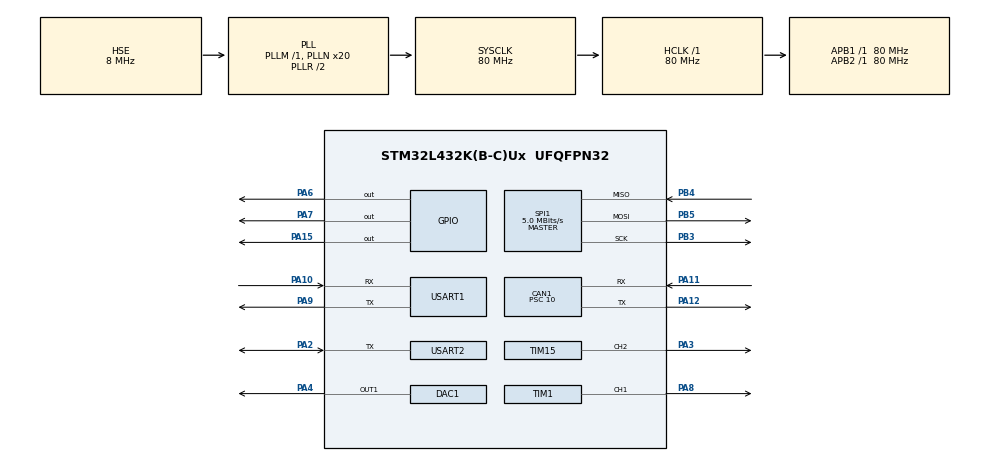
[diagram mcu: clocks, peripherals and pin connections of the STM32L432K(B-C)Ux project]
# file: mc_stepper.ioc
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ADC1.Channel-0\#ChannelRegularConversion=ADC_CHANNEL_VREFINT
ADC1.Channel-1\#ChannelRegularConversion=ADC_CHANNEL_TEMPSENSOR
ADC1.NbrOfConversion=2
ADC1.NbrOfConversionFlag=1
ADC1.OffsetNumber-0\#ChannelRegularConversion=ADC_OFFSET_NONE
ADC1.OffsetNumber-1\#ChannelRegularConversion=ADC_OFFSET_NONE
ADC1.Overrun=ADC_OVR_DATA_OVERWRITTEN
ADC1.OversamplingMode=DISABLE
ADC1.Rank-0\#ChannelRegularConversion=1
ADC1.Rank-1\#ChannelRegularConversion=2
ADC1.SamplingTime-0\#ChannelRegularConversion=ADC_SAMPLETIME_640CYCLES_5
ADC1.SamplingTime-1\#ChannelRegularConversion=ADC_SAMPLETIME_640CYCLES_5
ADC1.master=1
CAN1.ABOM=ENABLE
CAN1.BS1=CAN_BS1_13TQ
CAN1.BS2=CAN_BS2_2TQ
CAN1.CalculateBaudRate=500000
CAN1.CalculateTimeBit=2000
CAN1.CalculateTimeQuantum=125.0
CAN1.NART=ENABLE
CAN1.Prescaler=10
Dma.ADC1.3.Direction=DMA_PERIPH_TO_MEMORY
Dma.ADC1.3.Instance=DMA1_Channel1
Dma.ADC1.3.MemDataAlignment=DMA_MDATAALIGN_WORD
Dma.ADC1.3.MemInc=DMA_MINC_ENABLE
Dma.ADC1.3.Mode=DMA_NORMAL
Dma.ADC1.3.PeriphDataAlignment=DMA_PDATAALIGN_WORD
Dma.ADC1.3.PeriphInc=DMA_PINC_DISABLE
Dma.ADC1.3.Priority=DMA_PRIORITY_LOW
Dma.Request0=TIM1_CH1
Dma.Request1=USART1_RX
Dma.Request2=USART1_TX
Dma.Request3=ADC1
Dma.TIM1_CH1.0.Direction=DMA_MEMORY_TO_PERIPH
Dma.TIM1_CH1.0.Instance=DMA1_Channel2
Dma.TIM1_CH1.0.MemDataAlignment=DMA_MDATAALIGN_HALFWORD
Dma.TIM1_CH1.0.MemInc=DMA_MINC_ENABLE
Dma.TIM1_CH1.0.Mode=DMA_NORMAL
Dma.TIM1_CH1.0.PeriphDataAlignment=DMA_PDATAALIGN_HALFWORD
Dma.TIM1_CH1.0.PeriphInc=DMA_PINC_DISABLE
Dma.TIM1_CH1.0.Priority=DMA_PRIORITY_LOW
Dma.USART1_RX.1.Direction=DMA_PERIPH_TO_MEMORY
Dma.USART1_RX.1.Instance=DMA1_Channel5
Dma.USART1_RX.1.MemDataAlignment=DMA_MDATAALIGN_BYTE
Dma.USART1_RX.1.MemInc=DMA_MINC_ENABLE
Dma.USART1_RX.1.Mode=DMA_NORMAL
Dma.USART1_RX.1.PeriphDataAlignment=DMA_PDATAALIGN_BYTE
Dma.USART1_RX.1.PeriphInc=DMA_PINC_DISABLE
Dma.USART1_RX.1.Priority=DMA_PRIORITY_LOW
Dma.USART1_TX.2.Direction=DMA_MEMORY_TO_PERIPH
Dma.USART1_TX.2.Instance=DMA1_Channel4
Dma.USART1_TX.2.MemDataAlignment=DMA_MDATAALIGN_BYTE
Dma.USART1_TX.2.MemInc=DMA_MINC_ENABLE
Dma.USART1_TX.2.Mode=DMA_NORMAL
Dma.USART1_TX.2.PeriphDataAlignment=DMA_PDATAALIGN_BYTE
Dma.USART1_TX.2.PeriphInc=DMA_PINC_DISABLE
Dma.USART1_TX.2.Priority=DMA_PRIORITY_LOW
Mcu.Family=STM32L4
Mcu.Name=STM32L432K(B-C)Ux
Mcu.Package=UFQFPN32
NVIC.CAN1_RX0_IRQn=true\:0\:0\:false\:false\:true\:true\:true\:true
NVIC.CAN1_RX1_IRQn=true\:0\:0\:false\:false\:true\:true\:true\:true
NVIC.DMA1_Channel1_IRQn=true\:0\:0\:false\:false\:true\:false\:true\:true
NVIC.DMA1_Channel2_IRQn=true\:0\:0\:false\:false\:true\:false\:true\:true
NVIC.DMA1_Channel4_IRQn=true\:0\:0\:false\:false\:true\:false\:true\:true
NVIC.DMA1_Channel5_IRQn=true\:0\:0\:false\:false\:true\:false\:true\:true
NVIC.PriorityGroup=NVIC_PRIORITYGROUP_4
NVIC.TIM1_BRK_TIM15_IRQn=true\:0\:0\:false\:false\:true\:true\:true\:true
NVIC.TIM1_UP_TIM16_IRQn=true\:5\:0\:true\:false\:true\:false\:true\:true
PA0.Mode=HSE-External-Clock-Source-for-LittleOrca
PA0.Signal=RCC_CK_IN
PA10.Mode=Asynchronous
PA10.Signal=USART1_RX
PA11.Mode=CAN_Activate
PA11.Signal=CAN1_RX
PA12.Mode=CAN_Activate
PA12.Signal=CAN1_TX
PA13\ (JTMS-SWDIO).Mode=Serial_Wire
PA13\ (JTMS-SWDIO).Signal=SYS_JTMS-SWDIO
PA14\ (JTCK-SWCLK).Mode=Serial_Wire
PA14\ (JTCK-SWCLK).Signal=SYS_JTCK-SWCLK
PA15\ (JTDI).GPIO_Speed=GPIO_SPEED_FREQ_VERY_HIGH
PA15\ (JTDI).PinState=GPIO_PIN_SET
PA15\ (JTDI).Signal=GPIO_Output
PA2.Mode=Half_duplex(single_wire_mode)
PA2.Signal=USART2_TX
PA3.Signal=S_TIM15_CH2
PA4.Signal=COMP_DAC11_group
PA6.Signal=GPIO_Output
PA7.PinState=GPIO_PIN_SET
PA7.Signal=GPIO_Output
PA8.Signal=S_TIM1_CH1
PA9.Mode=Asynchronous
PA9.Signal=USART1_TX
PB3\ (JTDO-TRACESWO).Mode=Full_Duplex_Master
PB3\ (JTDO-TRACESWO).Signal=SPI1_SCK
PB4\ (NJTRST).Mode=Full_Duplex_Master
PB4\ (NJTRST).Signal=SPI1_MISO
PB5.Mode=Full_Duplex_Master
PB5.Signal=SPI1_MOSI
ProjectManager.HeapSize=0x200
ProjectManager.StackSize=0x400
ProjectManager.TargetToolchain=CMake
RCC.ADCFreq_Value=32000000
RCC.AHBFreq_Value=80000000
RCC.APB1Freq_Value=80000000
RCC.APB1TimFreq_Value=80000000
RCC.APB2Freq_Value=80000000
RCC.APB2TimFreq_Value=80000000
RCC.CortexFreq_Value=80000000
RCC.HCLKFreq_Value=80000000
RCC.HSE_VALUE=8000000
RCC.HSI48_VALUE=48000000
RCC.HSI_VALUE=16000000
RCC.LSE_VALUE=32768
RCC.MSI_VALUE=4000000
RCC.PLLN=20
RCC.PLLSourceVirtual=RCC_PLLSOURCE_HSE
RCC.SYSCLKFreq_VALUE=80000000
RCC.SYSCLKSource=RCC_SYSCLKSOURCE_PLLCLK
RCC.USBFreq_Value=32000000
RCC.VCOOutputFreq_Value=160000000
SH.COMP_DAC11_group.0=DAC1_OUT1,DAC_OUT1
SH.S_TIM15_CH2.0=TIM15_CH2,Output Compare2 CH2
SH.S_TIM1_CH1.0=TIM1_CH1,PWM Generation1 CH1
SPI1.BaudRatePrescaler=SPI_BAUDRATEPRESCALER_16
SPI1.CLKPhase=SPI_PHASE_2EDGE
SPI1.CalculateBaudRate=5.0 MBits/s
SPI1.DataSize=SPI_DATASIZE_16BIT
SPI1.Direction=SPI_DIRECTION_2LINES
SPI1.Mode=SPI_MODE_MASTER
SPI1.VirtualType=VM_MASTER
TIM1.Channel-PWM\ Generation1\ CH1=TIM_CHANNEL_1
TIM1.Period=25-1
TIM1.Prescaler=3-1
TIM15.Channel-Output\ Compare2\ CH2=TIM_CHANNEL_2
TIM15.OCMode_2=TIM_OCMODE_TOGGLE
TIM15.Prescaler=80-1
TIM16.Channel=TIM_CHANNEL_1
TIM16.Prescaler=80-1
USART1.VirtualMode-Asynchronous=VM_ASYNC
USART2.VirtualMode-Half_duplex(single_wire_mode)=VM_ASYNC
VP_ADC1_TempSens_Input.Mode=IN-TempSens
VP_ADC1_Vref_Input.Mode=IN-Vrefint
VP_RTC_VS_RTC_Activate.Mode=RTC_Enabled
VP_RTC_VS_RTC_Calendar.Mode=RTC_Calendar
VP_TIM16_VS_ClockSourceINT.Mode=Enable_Timer
VP_TIM16_VS_no_output1.Mode=PWM Generation1 No Output
board=custom

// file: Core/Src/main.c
/* USER CODE BEGIN Header */
/**
  ******************************************************************************
  * @file           : main.c
  * @brief          : Main program body
  ******************************************************************************
  * @attention
  *
  * Copyright (c) 2025 STMicroelectronics.
  * All rights reserved.
  *
  * This software is licensed under terms that can be found in the LICENSE file
  * in the root directory of this software component.
  * If no LICENSE file comes with this software, it is provided AS-IS.
  *
  ******************************************************************************
  */
/* USER CODE END Header */
#include "main.h"

/* USER CODE BEGIN Includes */
#include "can_driver/can_id_allocatee.h"
#include "comm.h"
#include "init.h"
#include "run.h"
/* USER CODE END Includes */

ADC_HandleTypeDef hadc1;
DMA_HandleTypeDef hdma_adc1;

CAN_HandleTypeDef hcan1;

DAC_HandleTypeDef hdac1;

RTC_HandleTypeDef hrtc;

SPI_HandleTypeDef hspi1;

TIM_HandleTypeDef htim1;
TIM_HandleTypeDef htim15;
TIM_HandleTypeDef htim16;
DMA_HandleTypeDef hdma_tim1_ch1;

UART_HandleTypeDef huart1;
UART_HandleTypeDef huart2;
DMA_HandleTypeDef hdma_usart1_rx;
DMA_HandleTypeDef hdma_usart1_tx;

void SystemClock_Config(void);
static void MX_GPIO_Init(void);
static void MX_DMA_Init(void);
static void MX_CAN1_Init(void);
static void MX_USART1_UART_Init(void);
static void MX_SPI1_Init(void);
static void MX_TIM15_Init(void);
static void MX_USART2_UART_Init(void);
static void MX_TIM1_Init(void);
static void MX_DAC1_Init(void);
static void MX_RTC_Init(void);
static void MX_TIM16_Init(void);
static void MX_ADC1_Init(void);

int main(void)
{

  /* MCU Configuration--------------------------------------------------------*/

  /* Reset of all peripherals, Initializes the Flash interface and the Systick. */
  HAL_Init();

  /* Configure the system clock */
  SystemClock_Config();

  /* Initialize all configured peripherals */
  MX_GPIO_Init();
  MX_DMA_Init();
  MX_CAN1_Init();
  MX_USART1_UART_Init();
  MX_SPI1_Init();
  MX_TIM15_Init();
  MX_USART2_UART_Init();
  MX_TIM1_Init();
  MX_DAC1_Init();
  MX_RTC_Init();
  MX_TIM16_Init();
  MX_ADC1_Init();

  /* Infinite loop */
  /* USER CODE BEGIN WHILE */
  mc_stepper_init();

  while (1) {
    mc_stepper_run();
    /* USER CODE END WHILE */

  }
}

void SystemClock_Config(void)
{
  RCC_OscInitTypeDef RCC_OscInitStruct = {0};
  RCC_ClkInitTypeDef RCC_ClkInitStruct = {0};

  /** Configure the main internal regulator output voltage
  */
  if (HAL_PWREx_ControlVoltageScaling(PWR_REGULATOR_VOLTAGE_SCALE1) != HAL_OK)
  {
    Error_Handler();
  }

  /** Initializes the RCC Oscillators according to the specified parameters
  * in the RCC_OscInitTypeDef structure.
  */
  RCC_OscInitStruct.OscillatorType = RCC_OSCILLATORTYPE_LSI|RCC_OSCILLATORTYPE_HSE;
  RCC_OscInitStruct.HSEState = RCC_HSE_BYPASS;
  RCC_OscInitStruct.LSIState = RCC_LSI_ON;
  RCC_OscInitStruct.PLL.PLLState = RCC_PLL_ON;
  RCC_OscInitStruct.PLL.PLLSource = RCC_PLLSOURCE_HSE;
  RCC_OscInitStruct.PLL.PLLM = 1;
  RCC_OscInitStruct.PLL.PLLN = 20;
  RCC_OscInitStruct.PLL.PLLP = RCC_PLLP_DIV7;
  RCC_OscInitStruct.PLL.PLLQ = RCC_PLLQ_DIV2;
  RCC_OscInitStruct.PLL.PLLR = RCC_PLLR_DIV2;
  if (HAL_RCC_OscConfig(&RCC_OscInitStruct) != HAL_OK)
  {
    Error_Handler();
  }

  /** Initializes the CPU, AHB and APB buses clocks
  */
  RCC_ClkInitStruct.ClockType = RCC_CLOCKTYPE_HCLK|RCC_CLOCKTYPE_SYSCLK
                              |RCC_CLOCKTYPE_PCLK1|RCC_CLOCKTYPE_PCLK2;
  RCC_ClkInitStruct.SYSCLKSource = RCC_SYSCLKSOURCE_PLLCLK;
  RCC_ClkInitStruct.AHBCLKDivider = RCC_SYSCLK_DIV1;
  RCC_ClkInitStruct.APB1CLKDivider = RCC_HCLK_DIV1;
  RCC_ClkInitStruct.APB2CLKDivider = RCC_HCLK_DIV1;

  if (HAL_RCC_ClockConfig(&RCC_ClkInitStruct, FLASH_LATENCY_4) != HAL_OK)
  {
    Error_Handler();
  }
}

static void MX_ADC1_Init(void)
{

  ADC_ChannelConfTypeDef sConfig = {0};

  /** Common config
  */
  hadc1.Instance = ADC1;
  hadc1.Init.ClockPrescaler = ADC_CLOCK_ASYNC_DIV1;
  hadc1.Init.Resolution = ADC_RESOLUTION_12B;
  hadc1.Init.DataAlign = ADC_DATAALIGN_RIGHT;
  hadc1.Init.ScanConvMode = ADC_SCAN_ENABLE;
  hadc1.Init.EOCSelection = ADC_EOC_SINGLE_CONV;
  hadc1.Init.LowPowerAutoWait = DISABLE;
  hadc1.Init.ContinuousConvMode = DISABLE;
  hadc1.Init.NbrOfConversion = 2;
  hadc1.Init.DiscontinuousConvMode = DISABLE;
  hadc1.Init.ExternalTrigConv = ADC_SOFTWARE_START;
  hadc1.Init.ExternalTrigConvEdge = ADC_EXTERNALTRIGCONVEDGE_NONE;
  hadc1.Init.DMAContinuousRequests = DISABLE;
  hadc1.Init.Overrun = ADC_OVR_DATA_OVERWRITTEN;
  hadc1.Init.OversamplingMode = DISABLE;
  if (HAL_ADC_Init(&hadc1) != HAL_OK)
  {
    Error_Handler();
  }

  /** Configure Regular Channel
  */
  sConfig.Channel = ADC_CHANNEL_VREFINT;
  sConfig.Rank = ADC_REGULAR_RANK_1;
  sConfig.SamplingTime = ADC_SAMPLETIME_640CYCLES_5;
  sConfig.SingleDiff = ADC_SINGLE_ENDED;
  sConfig.OffsetNumber = ADC_OFFSET_NONE;
  sConfig.Offset = 0;
  if (HAL_ADC_ConfigChannel(&hadc1, &sConfig) != HAL_OK)
  {
    Error_Handler();
  }

  /** Configure Regular Channel
  */
  sConfig.Channel = ADC_CHANNEL_TEMPSENSOR;
  sConfig.Rank = ADC_REGULAR_RANK_2;
  if (HAL_ADC_ConfigChannel(&hadc1, &sConfig) != HAL_OK)
  {
    Error_Handler();
  }

}

static void MX_CAN1_Init(void)
{

  hcan1.Instance = CAN1;
  hcan1.Init.Prescaler = 10;
  hcan1.Init.Mode = CAN_MODE_NORMAL;
  hcan1.Init.SyncJumpWidth = CAN_SJW_1TQ;
  hcan1.Init.TimeSeg1 = CAN_BS1_13TQ;
  hcan1.Init.TimeSeg2 = CAN_BS2_2TQ;
  hcan1.Init.TimeTriggeredMode = DISABLE;
  hcan1.Init.AutoBusOff = ENABLE;
  hcan1.Init.AutoWakeUp = DISABLE;
  hcan1.Init.AutoRetransmission = ENABLE;
  hcan1.Init.ReceiveFifoLocked = DISABLE;
  hcan1.Init.TransmitFifoPriority = DISABLE;
  if (HAL_CAN_Init(&hcan1) != HAL_OK)
  {
    Error_Handler();
  }

}

static void MX_DAC1_Init(void)
{

  DAC_ChannelConfTypeDef sConfig = {0};

  /** DAC Initialization
  */
  hdac1.Instance = DAC1;
  if (HAL_DAC_Init(&hdac1) != HAL_OK)
  {
    Error_Handler();
  }

  /** DAC channel OUT1 config
  */
  sConfig.DAC_SampleAndHold = DAC_SAMPLEANDHOLD_DISABLE;
  sConfig.DAC_Trigger = DAC_TRIGGER_NONE;
  sConfig.DAC_OutputBuffer = DAC_OUTPUTBUFFER_ENABLE;
  sConfig.DAC_ConnectOnChipPeripheral = DAC_CHIPCONNECT_DISABLE;
  sConfig.DAC_UserTrimming = DAC_TRIMMING_FACTORY;
  if (HAL_DAC_ConfigChannel(&hdac1, &sConfig, DAC_CHANNEL_1) != HAL_OK)
  {
    Error_Handler();
  }

}

static void MX_RTC_Init(void)
{

  RTC_TimeTypeDef sTime = {0};
  RTC_DateTypeDef sDate = {0};

  /** Initialize RTC Only
  */
  hrtc.Instance = RTC;
  hrtc.Init.HourFormat = RTC_HOURFORMAT_24;
  hrtc.Init.AsynchPrediv = 127;
  hrtc.Init.SynchPrediv = 255;
  hrtc.Init.OutPut = RTC_OUTPUT_DISABLE;
  hrtc.Init.OutPutRemap = RTC_OUTPUT_REMAP_NONE;
  hrtc.Init.OutPutPolarity = RTC_OUTPUT_POLARITY_HIGH;
  hrtc.Init.OutPutType = RTC_OUTPUT_TYPE_OPENDRAIN;
  if (HAL_RTC_Init(&hrtc) != HAL_OK)
  {
    Error_Handler();
  }

  /** Initialize RTC and set the Time and Date
  */
  sTime.Hours = 0x0;
  sTime.Minutes = 0x0;
  sTime.Seconds = 0x0;
  sTime.DayLightSaving = RTC_DAYLIGHTSAVING_NONE;
  sTime.StoreOperation = RTC_STOREOPERATION_RESET;
  if (HAL_RTC_SetTime(&hrtc, &sTime, RTC_FORMAT_BCD) != HAL_OK)
  {
    Error_Handler();
  }
  sDate.WeekDay = RTC_WEEKDAY_MONDAY;
  sDate.Month = RTC_MONTH_JANUARY;
  sDate.Date = 0x1;
  sDate.Year = 0x0;

  if (HAL_RTC_SetDate(&hrtc, &sDate, RTC_FORMAT_BCD) != HAL_OK)
  {
    Error_Handler();
  }

}

static void MX_SPI1_Init(void)
{

  /* SPI1 parameter configuration*/
  hspi1.Instance = SPI1;
  hspi1.Init.Mode = SPI_MODE_MASTER;
  hspi1.Init.Direction = SPI_DIRECTION_2LINES;
  hspi1.Init.DataSize = SPI_DATASIZE_16BIT;
  hspi1.Init.CLKPolarity = SPI_POLARITY_LOW;
  hspi1.Init.CLKPhase = SPI_PHASE_2EDGE;
  hspi1.Init.NSS = SPI_NSS_SOFT;
  hspi1.Init.BaudRatePrescaler = SPI_BAUDRATEPRESCALER_16;
  hspi1.Init.FirstBit = SPI_FIRSTBIT_MSB;
  hspi1.Init.TIMode = SPI_TIMODE_DISABLE;
  hspi1.Init.CRCCalculation = SPI_CRCCALCULATION_DISABLE;
  hspi1.Init.CRCPolynomial = 7;
  hspi1.Init.CRCLength = SPI_CRC_LENGTH_DATASIZE;
  hspi1.Init.NSSPMode = SPI_NSS_PULSE_DISABLE;
  if (HAL_SPI_Init(&hspi1) != HAL_OK)
  {
    Error_Handler();
  }

}

static void MX_TIM1_Init(void)
{

  TIM_MasterConfigTypeDef sMasterConfig = {0};
  TIM_OC_InitTypeDef sConfigOC = {0};
  TIM_BreakDeadTimeConfigTypeDef sBreakDeadTimeConfig = {0};

  htim1.Instance = TIM1;
  htim1.Init.Prescaler = 3-1;
  htim1.Init.CounterMode = TIM_COUNTERMODE_UP;
  htim1.Init.Period = 25-1;
  htim1.Init.ClockDivision = TIM_CLOCKDIVISION_DIV1;
  htim1.Init.RepetitionCounter = 0;
  htim1.Init.AutoReloadPreload = TIM_AUTORELOAD_PRELOAD_DISABLE;
  if (HAL_TIM_PWM_Init(&htim1) != HAL_OK)
  {
    Error_Handler();
  }
  sMasterConfig.MasterOutputTrigger = TIM_TRGO_RESET;
  sMasterConfig.MasterOutputTrigger2 = TIM_TRGO2_RESET;
  sMasterConfig.MasterSlaveMode = TIM_MASTERSLAVEMODE_DISABLE;
  if (HAL_TIMEx_MasterConfigSynchronization(&htim1, &sMasterConfig) != HAL_OK)
  {
    Error_Handler();
  }
  sConfigOC.OCMode = TIM_OCMODE_PWM1;
  sConfigOC.Pulse = 0;
  sConfigOC.OCPolarity = TIM_OCPOLARITY_HIGH;
  sConfigOC.OCNPolarity = TIM_OCNPOLARITY_HIGH;
  sConfigOC.OCFastMode = TIM_OCFAST_DISABLE;
  sConfigOC.OCIdleState = TIM_OCIDLESTATE_RESET;
  sConfigOC.OCNIdleState = TIM_OCNIDLESTATE_RESET;
  if (HAL_TIM_PWM_ConfigChannel(&htim1, &sConfigOC, TIM_CHANNEL_1) != HAL_OK)
  {
    Error_Handler();
  }
  sBreakDeadTimeConfig.OffStateRunMode = TIM_OSSR_DISABLE;
  sBreakDeadTimeConfig.OffStateIDLEMode = TIM_OSSI_DISABLE;
  sBreakDeadTimeConfig.LockLevel = TIM_LOCKLEVEL_OFF;
  sBreakDeadTimeConfig.DeadTime = 0;
  sBreakDeadTimeConfig.BreakState = TIM_BREAK_DISABLE;
  sBreakDeadTimeConfig.BreakPolarity = TIM_BREAKPOLARITY_HIGH;
  sBreakDeadTimeConfig.BreakFilter = 0;
  sBreakDeadTimeConfig.Break2State = TIM_BREAK2_DISABLE;
  sBreakDeadTimeConfig.Break2Polarity = TIM_BREAK2POLARITY_HIGH;
  sBreakDeadTimeConfig.Break2Filter = 0;
  sBreakDeadTimeConfig.AutomaticOutput = TIM_AUTOMATICOUTPUT_DISABLE;
  if (HAL_TIMEx_ConfigBreakDeadTime(&htim1, &sBreakDeadTimeConfig) != HAL_OK)
  {
    Error_Handler();
  }
  HAL_TIM_MspPostInit(&htim1);

}

static void MX_TIM15_Init(void)
{

  TIM_MasterConfigTypeDef sMasterConfig = {0};
  TIM_OC_InitTypeDef sConfigOC = {0};
  TIM_BreakDeadTimeConfigTypeDef sBreakDeadTimeConfig = {0};

  htim15.Instance = TIM15;
  htim15.Init.Prescaler = 80-1;
  htim15.Init.CounterMode = TIM_COUNTERMODE_UP;
  htim15.Init.Period = 65535;
  htim15.Init.ClockDivision = TIM_CLOCKDIVISION_DIV1;
  htim15.Init.RepetitionCounter = 0;
  htim15.Init.AutoReloadPreload = TIM_AUTORELOAD_PRELOAD_DISABLE;
  if (HAL_TIM_OC_Init(&htim15) != HAL_OK)
  {
    Error_Handler();
  }
  sMasterConfig.MasterOutputTrigger = TIM_TRGO_RESET;
  sMasterConfig.MasterSlaveMode = TIM_MASTERSLAVEMODE_DISABLE;
  if (HAL_TIMEx_MasterConfigSynchronization(&htim15, &sMasterConfig) != HAL_OK)
  {
    Error_Handler();
  }
  sConfigOC.OCMode = TIM_OCMODE_TOGGLE;
  sConfigOC.Pulse = 0;
  sConfigOC.OCPolarity = TIM_OCPOLARITY_HIGH;
  sConfigOC.OCNPolarity = TIM_OCNPOLARITY_HIGH;
  sConfigOC.OCFastMode = TIM_OCFAST_DISABLE;
  sConfigOC.OCIdleState = TIM_OCIDLESTATE_RESET;
  sConfigOC.OCNIdleState = TIM_OCNIDLESTATE_RESET;
  if (HAL_TIM_OC_ConfigChannel(&htim15, &sConfigOC, TIM_CHANNEL_2) != HAL_OK)
  {
    Error_Handler();
  }
  sBreakDeadTimeConfig.OffStateRunMode = TIM_OSSR_DISABLE;
  sBreakDeadTimeConfig.OffStateIDLEMode = TIM_OSSI_DISABLE;
  sBreakDeadTimeConfig.LockLevel = TIM_LOCKLEVEL_OFF;
  sBreakDeadTimeConfig.DeadTime = 0;
  sBreakDeadTimeConfig.BreakState = TIM_BREAK_DISABLE;
  sBreakDeadTimeConfig.BreakPolarity = TIM_BREAKPOLARITY_HIGH;
  sBreakDeadTimeConfig.AutomaticOutput = TIM_AUTOMATICOUTPUT_DISABLE;
  if (HAL_TIMEx_ConfigBreakDeadTime(&htim15, &sBreakDeadTimeConfig) != HAL_OK)
  {
    Error_Handler();
  }
  HAL_TIM_MspPostInit(&htim15);

}

static void MX_TIM16_Init(void)
{

  TIM_OC_InitTypeDef sConfigOC = {0};
  TIM_BreakDeadTimeConfigTypeDef sBreakDeadTimeConfig = {0};

  htim16.Instance = TIM16;
  htim16.Init.Prescaler = 80-1;
  htim16.Init.CounterMode = TIM_COUNTERMODE_UP;
  htim16.Init.Period = 65535;
  htim16.Init.ClockDivision = TIM_CLOCKDIVISION_DIV1;
  htim16.Init.RepetitionCounter = 0;
  htim16.Init.AutoReloadPreload = TIM_AUTORELOAD_PRELOAD_DISABLE;
  if (HAL_TIM_Base_Init(&htim16) != HAL_OK)
  {
    Error_Handler();
  }
  if (HAL_TIM_PWM_Init(&htim16) != HAL_OK)
  {
    Error_Handler();
  }
  sConfigOC.OCMode = TIM_OCMODE_PWM1;
  sConfigOC.Pulse = 0;
  sConfigOC.OCPolarity = TIM_OCPOLARITY_HIGH;
  sConfigOC.OCNPolarity = TIM_OCNPOLARITY_HIGH;
  sConfigOC.OCFastMode = TIM_OCFAST_DISABLE;
  sConfigOC.OCIdleState = TIM_OCIDLESTATE_RESET;
  sConfigOC.OCNIdleState = TIM_OCNIDLESTATE_RESET;
  if (HAL_TIM_PWM_ConfigChannel(&htim16, &sConfigOC, TIM_CHANNEL_1) != HAL_OK)
  {
    Error_Handler();
  }
  sBreakDeadTimeConfig.OffStateRunMode = TIM_OSSR_DISABLE;
  sBreakDeadTimeConfig.OffStateIDLEMode = TIM_OSSI_DISABLE;
  sBreakDeadTimeConfig.LockLevel = TIM_LOCKLEVEL_OFF;
  sBreakDeadTimeConfig.DeadTime = 0;
  sBreakDeadTimeConfig.BreakState = TIM_BREAK_DISABLE;
  sBreakDeadTimeConfig.BreakPolarity = TIM_BREAKPOLARITY_HIGH;
  sBreakDeadTimeConfig.AutomaticOutput = TIM_AUTOMATICOUTPUT_DISABLE;
  if (HAL_TIMEx_ConfigBreakDeadTime(&htim16, &sBreakDeadTimeConfig) != HAL_OK)
  {
    Error_Handler();
  }

}

static void MX_USART1_UART_Init(void)
{

  huart1.Instance = USART1;
  huart1.Init.BaudRate = 115200;
  huart1.Init.WordLength = UART_WORDLENGTH_8B;
  huart1.Init.StopBits = UART_STOPBITS_1;
  huart1.Init.Parity = UART_PARITY_NONE;
  huart1.Init.Mode = UART_MODE_TX_RX;
  huart1.Init.HwFlowCtl = UART_HWCONTROL_NONE;
  huart1.Init.OverSampling = UART_OVERSAMPLING_16;
  huart1.Init.OneBitSampling = UART_ONE_BIT_SAMPLE_DISABLE;
  huart1.AdvancedInit.AdvFeatureInit = UART_ADVFEATURE_NO_INIT;
  if (HAL_UART_Init(&huart1) != HAL_OK)
  {
    Error_Handler();
  }

}

static void MX_USART2_UART_Init(void)
{

  huart2.Instance = USART2;
  huart2.Init.BaudRate = 115200;
  huart2.Init.WordLength = UART_WORDLENGTH_8B;
  huart2.Init.StopBits = UART_STOPBITS_1;
  huart2.Init.Parity = UART_PARITY_NONE;
  huart2.Init.Mode = UART_MODE_TX_RX;
  huart2.Init.HwFlowCtl = UART_HWCONTROL_NONE;
  huart2.Init.OverSampling = UART_OVERSAMPLING_16;
  huart2.Init.OneBitSampling = UART_ONE_BIT_SAMPLE_DISABLE;
  huart2.AdvancedInit.AdvFeatureInit = UART_ADVFEATURE_NO_INIT;
  if (HAL_HalfDuplex_Init(&huart2) != HAL_OK)
  {
    Error_Handler();
  }

}

static void MX_DMA_Init(void)
{

  /* DMA controller clock enable */
  __HAL_RCC_DMA1_CLK_ENABLE();

  /* DMA interrupt init */
  /* DMA1_Channel1_IRQn interrupt configuration */
  HAL_NVIC_SetPriority(DMA1_Channel1_IRQn, 0, 0);
  HAL_NVIC_EnableIRQ(DMA1_Channel1_IRQn);
  /* DMA1_Channel2_IRQn interrupt configuration */
  HAL_NVIC_SetPriority(DMA1_Channel2_IRQn, 0, 0);
  HAL_NVIC_EnableIRQ(DMA1_Channel2_IRQn);
  /* DMA1_Channel4_IRQn interrupt configuration */
  HAL_NVIC_SetPriority(DMA1_Channel4_IRQn, 0, 0);
  HAL_NVIC_EnableIRQ(DMA1_Channel4_IRQn);
  /* DMA1_Channel5_IRQn interrupt configuration */
  HAL_NVIC_SetPriority(DMA1_Channel5_IRQn, 0, 0);
  HAL_NVIC_EnableIRQ(DMA1_Channel5_IRQn);

}

static void MX_GPIO_Init(void)
{
  GPIO_InitTypeDef GPIO_InitStruct = {0};

  /* GPIO Ports Clock Enable */
  __HAL_RCC_GPIOA_CLK_ENABLE();
  __HAL_RCC_GPIOB_CLK_ENABLE();

  /*Configure GPIO pin Output Level */
  HAL_GPIO_WritePin(GPIOA, GPIO_PIN_6, GPIO_PIN_RESET);

  /*Configure GPIO pin Output Level */
  HAL_GPIO_WritePin(GPIOA, GPIO_PIN_7|GPIO_PIN_15, GPIO_PIN_SET);

  /*Configure GPIO pins : PA6 PA7 */
  GPIO_InitStruct.Pin = GPIO_PIN_6|GPIO_PIN_7;
  GPIO_InitStruct.Mode = GPIO_MODE_OUTPUT_PP;
  GPIO_InitStruct.Pull = GPIO_NOPULL;
  GPIO_InitStruct.Speed = GPIO_SPEED_FREQ_LOW;
  HAL_GPIO_Init(GPIOA, &GPIO_InitStruct);

  /*Configure GPIO pin : PA15 */
  GPIO_InitStruct.Pin = GPIO_PIN_15;
  GPIO_InitStruct.Mode = GPIO_MODE_OUTPUT_PP;
  GPIO_InitStruct.Pull = GPIO_NOPULL;
  GPIO_InitStruct.Speed = GPIO_SPEED_FREQ_VERY_HIGH;
  HAL_GPIO_Init(GPIOA, &GPIO_InitStruct);

}

void Error_Handler(void)
{
  __disable_irq();
  while (1)
  {
  }
}
